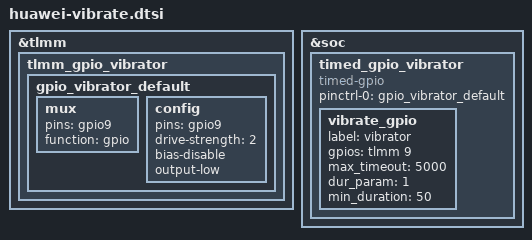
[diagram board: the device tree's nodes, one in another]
&tlmm {
	tlmm_gpio_vibrator {
		gpio_vibrator_default: gpio_vibrator_default {
			mux {
				pins = "gpio9";
				function = "gpio";
			};

			config {
				pins = "gpio9";
				drive-strength = <2>;
				bias-disable;
				output-low;
			};
		};
	};
};

&soc {
	timed_gpio_vibrator {
		compatible = "timed-gpio";
		pinctrl-names = "default";
		pinctrl-0 = <&gpio_vibrator_default>;

		vibrate_gpio {
			label = "vibrator";
			gpios = <&tlmm 9 0>;
			max_timeout = <5000>;
			dur_param = <1>;
			min_duration = <50>;
		};
	};
};

